# PT32G031xx register map
File version: 0.4
Registers are 32-bit, read-write, reset 0x0 unless marked. A register's access mark holds for its fields unless they carry their own. Offsets are from the block's base; [hi:lo] are bit positions; {n}, {i} and the like mark numbered series.

## ADC — Analog-to-digital converters
Base 0x40012400
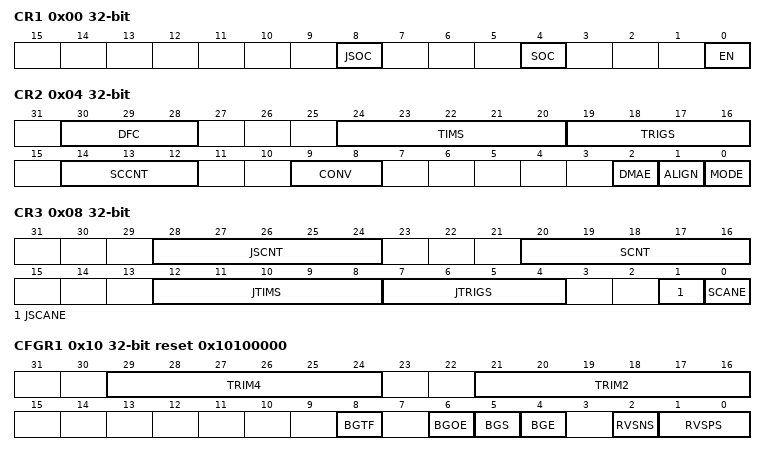
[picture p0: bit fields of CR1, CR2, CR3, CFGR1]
0x00 CR1 access per field — Control Register 1
  [8] JSOC wo — ADC start of injected conversion
  [4] SOC wo — ADC start on control
  [0] EN rw — ADC enable
0x04 CR2 — Control Register 2
  [30:28] DFC — Digital filter configuration
  [24:20] TIMS — ADC regular timer trigger source selection
  [19:16] TRIGS — ADC regular trigger source selection
  [14:12] SCCNT — Single conversion count control
  [9:8] CONV — ADC conversion control
  [2] DMAE — ADC DMA enable
  [1] ALIGN — ADC ALIGN
  [0] MODE — ADC regular conversion mode
0x08 CR3 — Control Register 3
  [28:24] JSCNT — ADC injected scan channel number configuration
  [20:16] SCNT — ADC regular scan channel number configuration
  [12:8] JTIMS — ADC injected timer trigger source selection
  [7:4] JTRIGS — ADC injected trigger source selection
  [1] JSCANE — ADC injected scan enable
  [0] SCANE — ADC regular scan enable
0x10 CFGR1 access per field reset 0x10100000 — Configuration Register 1
  [29:24] TRIM4 rw — BG4v0 offset trimming value
  [21:16] TRIM2 rw — BG2v0 offset trimming value
  [8] BGTF ro — BGREF offset trimming value source flag
  [6] BGOE rw — BGREF output
  [5] BGS rw — BGREF source selection
  [4] BGE rw — BGREF enable
  [2] RVSNS rw — Reference voltage source negative selection
  [1:0] RVSPS rw — Reference voltage source positive selection
0x14 CFGR2 — Configuration Register 2
  [21:16] CHS — ADC channel selection
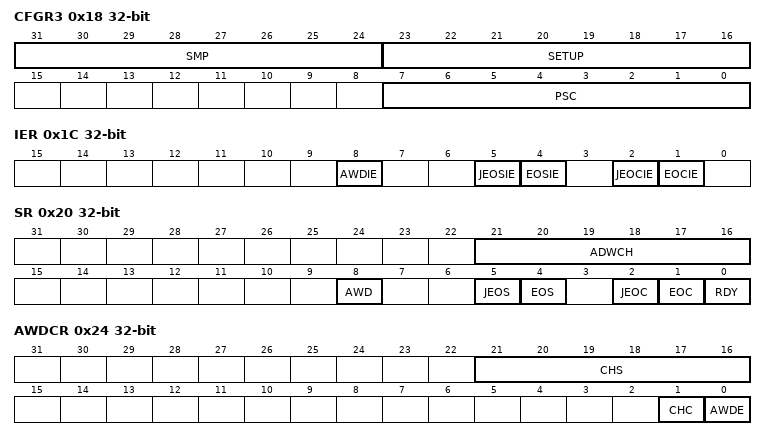
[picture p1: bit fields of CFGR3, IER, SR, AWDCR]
0x18 CFGR3 — Configuration Register 3
  [31:24] SMP — ADC sample time
  [23:16] SETUP — ADC channel setup time
  [7:0] PSC — ADC prescaler
0x1C IER — Interrupt Enable Register
  [8] AWDIE — Analog watchdog interrupt enable
  [5] JEOSIE — ADC injected channel end of scan interrupt enable
  [4] EOSIE — ADC end of scan interrupt enable
  [2] JEOCIE — ADC injected channel end of conversion interrupt enable
  [1] EOCIE — ADC end of conversion interrupt enable
0x20 SR access per field — Status Register
  [21:16] ADWCH ro — Analog watchdog channel selection
  [8] AWD rw — Analog watchdog flag
  [5] JEOS ro — ADC injected channel end of scan flag
  [4] EOS ro — ADC end of scan
  [2] JEOC ro — ADC injected channel end of conversion flag
  [1] EOC ro — ADC end of conversion
  [0] RDY ro — ADC ready
0x24 AWDCR — Analog Watchdog Configuration Register
  [21:16] CHS — Analog watchdog channel selection
  [1] CHC — Analog watchdog channel control
  [0] AWDE — Analog watchdog enable
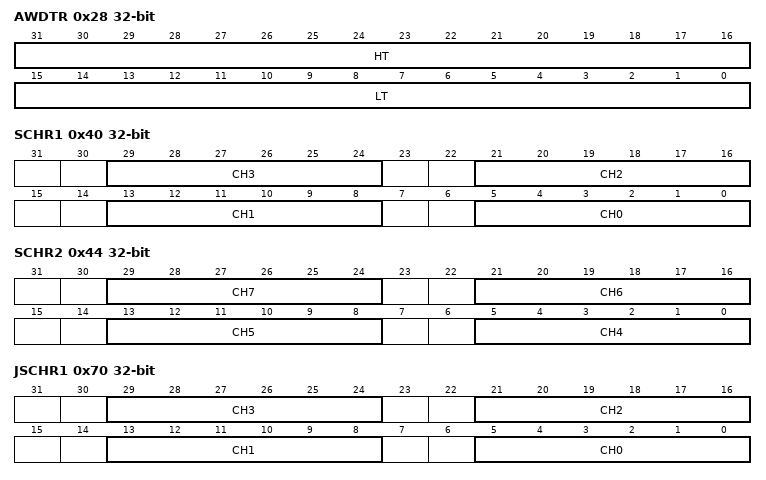
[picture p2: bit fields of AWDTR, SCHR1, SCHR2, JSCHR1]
0x28 AWDTR — Analog Watchdog Threshold Register
  [31:16] HT — Analog watchdog higher threshold
  [15:0] LT — Analog watchdog lower threshold
0x30 DR ro — Data Register
  [15:0] DATA — ADC data
0x40 SCHR1 — Regular Scan Channel Configuration Register 1
  [8n+5:8n] CH{n} (n=0..3) — ADC scan channel {n} selection
0x44 SCHR2 — Regular Scan Channel Configuration Register 2
  [8n-27:8n-32] CH{n} (n=4..7) — ADC scan channel {n} selection
0x70 JSCHR1 — Inject Scan Channel Configuration Register 1
  [8n+5:8n] CH{n} (n=0..3) — ADC inject channel {n} selection
{0x100+4i} SCHDR{i} ro (i=0..7) — Scan channel {i} data register
  [15:0] DATA — ADC data
{0x200+4i} JSCHDR{i} ro (i=0..3) — Inject Scan Channel {i} Data Register
  [15:0] DATA — ADC data

## TIM2 — Basic timer
Base 0x40001000
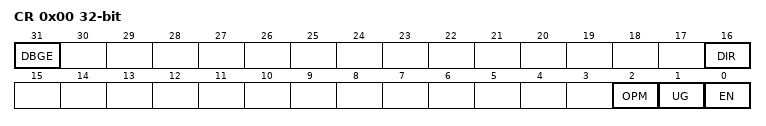
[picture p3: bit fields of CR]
0x00 CR access per field — Control Register
  [31] DBGE rw — TIM debug
  [16] DIR rw — Direction
  [2] OPM rw — One-pulse mode
  [1] UG wo — Counter Update generation
  [0] EN rw — Counter enable
0x40 SR1 — Status Register 1
  [0] ARF — auto reload flag
0x48 IER1 — Interrupt Enable Register 1
  [0] ARIE — Auto reload interrupt enable
0x58 PSCR — Prescaler Register
  [15:0] PSC — Prescaler value
0x5C PCNTR — Prescaler Counter Register
  [15:0] CNT — Prescaler counter value
0x60 CNTR — Counter Register
  [15:0] CNT — Counter value
0x64 ARR — Auto Reload Register
  [15:0] ARR — Auto reload value
